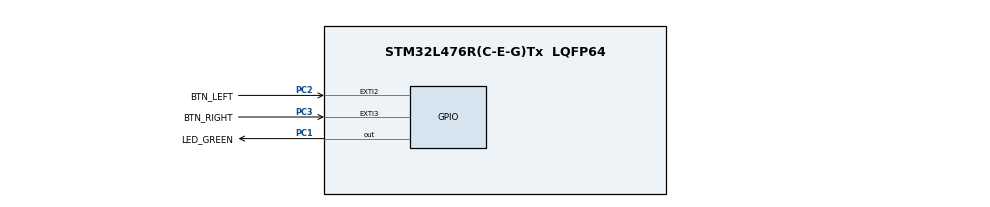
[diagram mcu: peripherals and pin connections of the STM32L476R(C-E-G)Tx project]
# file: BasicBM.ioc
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Mcu.Family=STM32L4
Mcu.Name=STM32L476R(C-E-G)Tx
Mcu.Package=LQFP64
NVIC.EXTI2_IRQn=true\:4\:0\:true\:false\:true\:true\:true\:true
NVIC.EXTI3_IRQn=true\:4\:0\:true\:false\:true\:true\:true\:true
NVIC.PriorityGroup=NVIC_PRIORITYGROUP_4
NVIC.TIM6_DAC_IRQn=true\:1\:0\:true\:false\:true\:true\:true\:true
PC1.GPIO_Label=LED_GREEN
PC1.GPIO_PuPd=GPIO_NOPULL
PC1.Signal=GPIO_Output
PC2.GPIO_Label=BTN_LEFT
PC2.GPIO_ModeDefaultEXTI=GPIO_MODE_IT_RISING_FALLING
PC2.GPIO_PuPd=GPIO_PULLUP
PC2.Signal=GPXTI2
PC3.GPIO_Label=BTN_RIGHT
PC3.GPIO_ModeDefaultEXTI=GPIO_MODE_IT_RISING_FALLING
PC3.GPIO_PuPd=GPIO_PULLUP
PC3.Signal=GPXTI3
ProjectManager.HeapSize=0x200
ProjectManager.StackSize=0x400
ProjectManager.TargetToolchain=STM32CubeIDE
RCC.HSE_VALUE=8000000
RCC.HSI_VALUE=16000000
RCC.LSE_VALUE=32768
RCC.MSI_VALUE=4000000
RCC.VCOOutputFreq_Value=32000000
TIM6.Period=39999
VP_TIM6_VS_ClockSourceINT.Mode=Enable_Timer
board=custom

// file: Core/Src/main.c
/* USER CODE BEGIN Header */
/**
  ******************************************************************************
  * @file           : main.c
  * @brief          : Main program body
  ******************************************************************************
  * @attention
  *
  * Copyright (c) 2024 STMicroelectronics.
  * All rights reserved.
  *
  * This software is licensed under terms that can be found in the LICENSE file
  * in the root directory of this software component.
  * If no LICENSE file comes with this software, it is provided AS-IS.
  *
  ******************************************************************************
  */
/* USER CODE END Header */
#include "main.h"
#include "tim.h"
#include "gpio.h"

void SystemClock_Config(void);

int main(void)
{

  /* MCU Configuration--------------------------------------------------------*/

  /* Reset of all peripherals, Initializes the Flash interface and the Systick. */
  HAL_Init();

  /* Configure the system clock */
  SystemClock_Config();

  /* Initialize all configured peripherals */
  MX_GPIO_Init();
  MX_TIM6_Init();
  /* USER CODE BEGIN 2 */
  /* initialize peripherals */
  // initialize Timer6
  HAL_TIM_Base_Start_IT(&htim6);

  // initial LED sequence
  gpio_InitSequence(100, 5);

  /* USER CODE END 2 */

  /* Infinite loop */
  /* USER CODE BEGIN WHILE */
  while (1)
  {
	  gpio_pollLedTimer();
	  gpio_pollLeftBtnTimer();
	  gpio_pollRightBtnTimer();
    /* USER CODE END WHILE */

  }
}

void SystemClock_Config(void)
{
  RCC_OscInitTypeDef RCC_OscInitStruct = {0};
  RCC_ClkInitTypeDef RCC_ClkInitStruct = {0};

  /** Configure the main internal regulator output voltage
  */
  if (HAL_PWREx_ControlVoltageScaling(PWR_REGULATOR_VOLTAGE_SCALE1) != HAL_OK)
  {
    Error_Handler();
  }

  /** Initializes the RCC Oscillators according to the specified parameters
  * in the RCC_OscInitTypeDef structure.
  */
  RCC_OscInitStruct.OscillatorType = RCC_OSCILLATORTYPE_MSI;
  RCC_OscInitStruct.MSIState = RCC_MSI_ON;
  RCC_OscInitStruct.MSICalibrationValue = 0;
  RCC_OscInitStruct.MSIClockRange = RCC_MSIRANGE_6;
  RCC_OscInitStruct.PLL.PLLState = RCC_PLL_NONE;
  if (HAL_RCC_OscConfig(&RCC_OscInitStruct) != HAL_OK)
  {
    Error_Handler();
  }

  /** Initializes the CPU, AHB and APB buses clocks
  */
  RCC_ClkInitStruct.ClockType = RCC_CLOCKTYPE_HCLK|RCC_CLOCKTYPE_SYSCLK
                              |RCC_CLOCKTYPE_PCLK1|RCC_CLOCKTYPE_PCLK2;
  RCC_ClkInitStruct.SYSCLKSource = RCC_SYSCLKSOURCE_MSI;
  RCC_ClkInitStruct.AHBCLKDivider = RCC_SYSCLK_DIV1;
  RCC_ClkInitStruct.APB1CLKDivider = RCC_HCLK_DIV1;
  RCC_ClkInitStruct.APB2CLKDivider = RCC_HCLK_DIV1;

  if (HAL_RCC_ClockConfig(&RCC_ClkInitStruct, FLASH_LATENCY_0) != HAL_OK)
  {
    Error_Handler();
  }
}

void Error_Handler(void)
{
  __disable_irq();
  while (1)
  {
  }
}
